# RK3399-AP register map
File version: 1
CPU: CA7 r0p1, little endian, MPU, FPU, I-cache, D-cache, VTOR, 4 interrupt priority bits, 32 interrupts
Registers are 32-bit, read-write, reset 0x0 unless marked. A register's access mark holds for its fields unless they carry their own. Offsets are from the block's base; [hi:lo] are bit positions.

## TIMER0
Base 0xFF850000
Same registers: PMUTIMER0 0xFF360000, PMUTIMER1 0xFF360020, TIMER1 0xFF850020, TIMER2 0xFF850040, TIMER3 0xFF850060, TIMER4 0xFF850080, TIMER5 0xFF850100, TIMER6 0xFF858000, TIMER7 0xFF858020, TIMER8 0xFF858040, TIMER9 0xFF858060, TIMER10 0xFF858080, TIMER11 0xFF858100, STIMER0 0xFF860000, STIMER1 0xFF860020, STIMER2 0xFF860040, STIMER3 0xFF860060, STIMER4 0xFF860080, STIMER5 0xFF860100, STIMER6 0xFF868000, STIMER7 0xFF868020, STIMER8 0xFF868040, STIMER9 0xFF868060, STIMER10 0xFF868080, STIMER11 0xFF868100
0x00 TIMER_n_LOAD_COUNT0 access not given — Timer n higher Load Count Register
0x04 TIMER_n_LOAD_COUNT1 access not given — Timer n higher Load Count Register
0x08 TIMER_n_CURRENT_VALUE0 access not given — Timer n Current Value Register
0x0C TIMER_n_CURRENT_VALUE1 access not given — Timer n Current Value Register
0x10 TIMER_n_LOAD_COUNT2 access not given — Timer n lower Load Count Register
0x14 TIMER_n_LOAD_COUNT3 access not given — Timer n lower Load Count Register
0x18 TIMER_n_INTSTATUS access not given — Timer Interrupt Stauts Register
0x1C TIMER_n_CONTROLREG access not given — Timer n Control Register

## MSCH0
Base 0xFFA84000
Same registers: MSCH1 0xFFA8C000
0x00 MSCH_Id_CoreId access not given reset 0xD867004 — Core ID register
0x04 MSCH_Id_RevisionId access not given reset 0x1AA00 — Revision ID register
0x08 MSCH_DeviceConf access not given — ddr configuration pointers
0x0C MSCH_DeviceSize access not given — ddr configuration sizes.
0x10 MSCH_DdrTimingA0 access not given reset 0x28140916 — DdrTimingA bank 0
0x14 MSCH_DdrTimingB0 access not given reset 0x40702 — DdrTimingB bank 0
0x18 MSCH_DdrTimingC0 access not given reset 0x2 — DdrTimingC bank 0
0x1C MSCH_DevToDev0 access not given reset 0x222 — Timing values concerning device to device data bus ownership c
0x110 MSCH_DdrMode access not given reset 0x4C — ddr mode definition.
0x1000 MSCH_AgingX0 access not given — Aging threshold multiplicator.

## ISP0_MMU0
Base 0xFF914000
Same registers: IEP_MMU 0xFF670800, VOPL_MMU 0xFF8F0300, VOPB_MMU 0xFF900300, ISP0_MMU1 0xFF915000, ISP1_MMU0 0xFF924000, ISP1_MMU1 0xFF925000, HDCP_MMU 0xFF930000
0x00 MMU_DTE_ADDR — MMU current page table address
  [31:0] MMU_DTE_ADDR — page table address
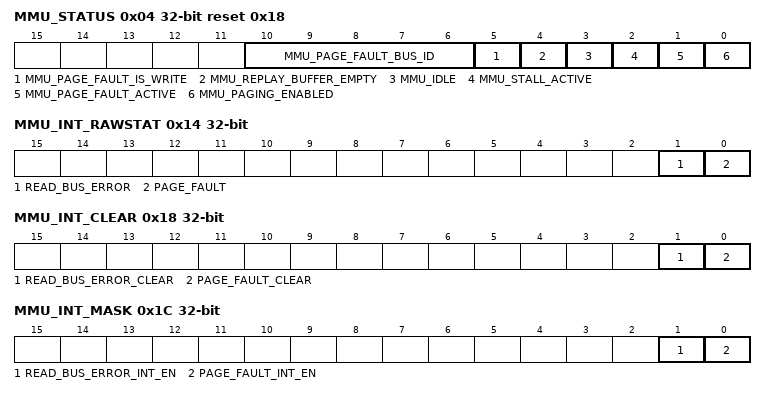
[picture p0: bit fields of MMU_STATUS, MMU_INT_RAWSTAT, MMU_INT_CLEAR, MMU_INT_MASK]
0x04 MMU_STATUS ro reset 0x18
  [10:6] MMU_PAGE_FAULT_BUS_ID — Index of master responsible for the last page fault
  [5] MMU_PAGE_FAULT_IS_WRITE — The direction of access for last page fault: 0: read 1:write
  [4] MMU_REPLAY_BUFFER_EMPTY — 1：The MMU replay buffer is empty.
  [3] MMU_IDLE — the MMu is idle when accesses are being translated and there are no unfinished translated access. The MMU_IDLE signal only reports idle when the MMU processor is idle and accesses are active on the external bus. Note: the MMU can be idle in page fault mode. 1: MMU is idle
  [2] MMU_STALL_ACTIVE — MMU stall mode currently enabled. The mode is enabled by command. 1: MMU is in stall active status
  [1] MMU_PAGE_FAULT_ACTIVE — MMU page fault mode currently enabled.The mode is enabled by command 1: page fault is active
  [0] MMU_PAGING_ENABLED — 0: paging is disabled 1: Paging is enabled
0x08 MMU_CMD — MMU command register
  [2:0] MMU_CMD — 0: MMU_ENABLE_PAGING. enable paging. 1: MMU_DISABLE_PAGING. disable paging. 2: MMU_ENABLE_STALL. turn on stall mode. 3: MMU_DISABLE_STALL. turn off stall mode. 4: MMU_ZAP_CACHE. zap the entire page table cache. 5: MMU_PAGE_FAULT_DONE. leave page fault mode. 6: MMU_FORCE_RESET. reset the mmu. The MMU_ENABLE_STALL command can always be issued. Other commands are ignored unless the MMU is idle or stalled.
0x0C MMU_PAGE_FAULT_ADDR ro — MMU logic address of last page fault register
  [31:0] MMU_PAGE_FAULT_ADDR — address of last page fault
0x10 MMU_ZAP_ONE_LINE — MMU zap cache line register
  [31:0] MMU_ZAP_ONE_LINE — address to be invalidated from the page table cache.
0x14 MMU_INT_RAWSTAT ro — MMU raw interrupt status register
  [1] READ_BUS_ERROR, [0] PAGE_FAULT
0x18 MMU_INT_CLEAR — MMU interrupt clear register
  [1] READ_BUS_ERROR_CLEAR — read bus error interrupt clear. write 1 to this register can clear read bus error interrupt.
  [0] PAGE_FAULT_CLEAR — page fault interrupt clear, write 1 to this register can clear page fault interrupt.
0x1C MMU_INT_MASK — MMU interrupt mask register
  [1] READ_BUS_ERROR_INT_EN — read bus error interrupt enable
  [0] PAGE_FAULT_INT_EN — page fault interrupt enable
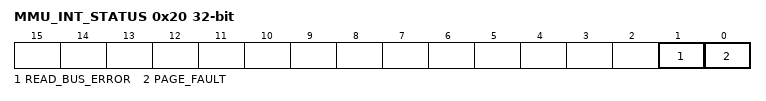
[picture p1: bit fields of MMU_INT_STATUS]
0x20 MMU_INT_STATUS access per field — MMU interrupt status register
  [1] READ_BUS_ERROR rw — read bus error interrupt
  [0] PAGE_FAULT ro — page fault interrupt
0x24 MMU_AUTO_GATING — clock atuo gating register
  [0] MMU_ATUO_GATING — mmu clock auto gating when it is 1, the mmu will auto gating itself
